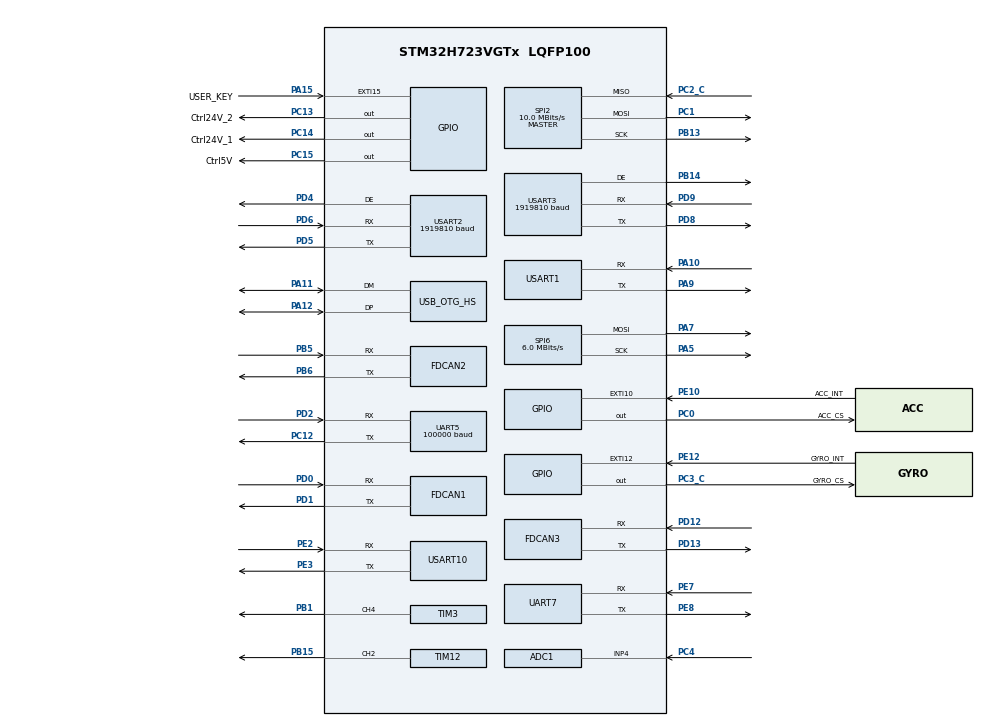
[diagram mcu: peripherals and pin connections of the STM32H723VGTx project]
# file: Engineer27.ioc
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ADC1.Channel-0\#ChannelRegularConversion=ADC_CHANNEL_4
ADC1.ContinuousConvMode=ENABLE
ADC1.ConversionDataManagement=ADC_CONVERSIONDATA_DMA_CIRCULAR
ADC1.NbrOfConversionFlag=1
ADC1.OffsetNumber-0\#ChannelRegularConversion=ADC_OFFSET_NONE
ADC1.OffsetSignedSaturation-0\#ChannelRegularConversion=DISABLE
ADC1.Overrun=ADC_OVR_DATA_OVERWRITTEN
ADC1.Rank-0\#ChannelRegularConversion=1
ADC1.SamplingTime-0\#ChannelRegularConversion=ADC_SAMPLETIME_64CYCLES_5
ADC1.master=1
ADC3.Channel-0\#ChannelRegularConversion=ADC_CHANNEL_TEMPSENSOR
ADC3.ContinuousConvMode=ENABLE
ADC3.ConversionDataManagement=ADC_CONVERSIONDATA_DMA_CIRCULAR
ADC3.DMAContinuousRequests=ENABLE
ADC3.NbrOfConversionFlag=1
ADC3.OffsetNumber-0\#ChannelRegularConversion=ADC_OFFSET_NONE
ADC3.OffsetSign-0\#ChannelRegularConversion=ADC3_OFFSET_SIGN_NEGATIVE
ADC3.Overrun=ADC_OVR_DATA_OVERWRITTEN
ADC3.Rank-0\#ChannelRegularConversion=1
ADC3.SamplingTime-0\#ChannelRegularConversion=ADC3_SAMPLETIME_92CYCLES_5
Bdma.ADC3.1.Direction=DMA_PERIPH_TO_MEMORY
Bdma.ADC3.1.EventEnable=DISABLE
Bdma.ADC3.1.Instance=BDMA_Channel1
Bdma.ADC3.1.MemDataAlignment=DMA_MDATAALIGN_HALFWORD
Bdma.ADC3.1.MemInc=DMA_MINC_ENABLE
Bdma.ADC3.1.Mode=DMA_CIRCULAR
Bdma.ADC3.1.PeriphDataAlignment=DMA_PDATAALIGN_HALFWORD
Bdma.ADC3.1.PeriphInc=DMA_PINC_DISABLE
Bdma.ADC3.1.Polarity=HAL_DMAMUX_REQ_GEN_RISING
Bdma.ADC3.1.Priority=DMA_PRIORITY_LOW
Bdma.ADC3.1.RequestNumber=1
Bdma.ADC3.1.SignalID=NONE
Bdma.ADC3.1.SyncEnable=DISABLE
Bdma.ADC3.1.SyncPolarity=HAL_DMAMUX_SYNC_NO_EVENT
Bdma.ADC3.1.SyncRequestNumber=1
Bdma.ADC3.1.SyncSignalID=NONE
Bdma.Request0=SPI6_TX
Bdma.Request1=ADC3
Bdma.RequestsNb=2
Bdma.SPI6_TX.0.Direction=DMA_MEMORY_TO_PERIPH
Bdma.SPI6_TX.0.EventEnable=DISABLE
Bdma.SPI6_TX.0.Instance=BDMA_Channel0
Bdma.SPI6_TX.0.MemDataAlignment=DMA_MDATAALIGN_BYTE
Bdma.SPI6_TX.0.MemInc=DMA_MINC_ENABLE
Bdma.SPI6_TX.0.Mode=DMA_NORMAL
Bdma.SPI6_TX.0.PeriphDataAlignment=DMA_PDATAALIGN_BYTE
Bdma.SPI6_TX.0.PeriphInc=DMA_PINC_DISABLE
Bdma.SPI6_TX.0.Polarity=HAL_DMAMUX_REQ_GEN_RISING
Bdma.SPI6_TX.0.Priority=DMA_PRIORITY_HIGH
Bdma.SPI6_TX.0.RequestNumber=1
Bdma.SPI6_TX.0.SignalID=NONE
Bdma.SPI6_TX.0.SyncEnable=DISABLE
Bdma.SPI6_TX.0.SyncPolarity=HAL_DMAMUX_SYNC_NO_EVENT
Bdma.SPI6_TX.0.SyncRequestNumber=1
Bdma.SPI6_TX.0.SyncSignalID=NONE
CORTEX_M7.AccessPermission_S-Cortex_Memory_Protection_Unit_Region1_Settings_S=MPU_REGION_FULL_ACCESS
CORTEX_M7.AccessPermission_S-Cortex_Memory_Protection_Unit_Region2_Settings_S=MPU_REGION_FULL_ACCESS
CORTEX_M7.AccessPermission_S-Cortex_Memory_Protection_Unit_Region3_Settings_S=MPU_REGION_FULL_ACCESS
CORTEX_M7.AccessPermission_S-Cortex_Memory_Protection_Unit_Region4_Settings_S=MPU_REGION_FULL_ACCESS
CORTEX_M7.AccessPermission_S-Cortex_Memory_Protection_Unit_Region5_Settings_S=MPU_REGION_FULL_ACCESS
CORTEX_M7.AccessPermission_S-Cortex_Memory_Protection_Unit_Region6_Settings_S=MPU_REGION_FULL_ACCESS
CORTEX_M7.AccessPermission_S-Cortex_Memory_Protection_Unit_Region7_Settings_S=MPU_REGION_FULL_ACCESS
CORTEX_M7.AccessPermission_Spec=MPU_REGION_NO_ACCESS
CORTEX_M7.BaseAddress_S-Cortex_Memory_Protection_Unit_Region1_Settings_S=0x00000000
CORTEX_M7.BaseAddress_S-Cortex_Memory_Protection_Unit_Region2_Settings_S=0x20000000
CORTEX_M7.BaseAddress_S-Cortex_Memory_Protection_Unit_Region3_Settings_S=0x24000000
CORTEX_M7.BaseAddress_S-Cortex_Memory_Protection_Unit_Region4_Settings_S=0x30000000
CORTEX_M7.BaseAddress_S-Cortex_Memory_Protection_Unit_Region5_Settings_S=0x38000000
CORTEX_M7.BaseAddress_S-Cortex_Memory_Protection_Unit_Region6_Settings_S=0x40000000
CORTEX_M7.BaseAddress_S-Cortex_Memory_Protection_Unit_Region7_Settings_S=0x8000000
CORTEX_M7.CPU_DCache=Enabled
CORTEX_M7.CPU_ICache=Enabled
CORTEX_M7.DisableExec_S-Cortex_Memory_Protection_Unit_Region2_Settings_S=MPU_INSTRUCTION_ACCESS_DISABLE
CORTEX_M7.DisableExec_S-Cortex_Memory_Protection_Unit_Region3_Settings_S=MPU_INSTRUCTION_ACCESS_DISABLE
CORTEX_M7.DisableExec_S-Cortex_Memory_Protection_Unit_Region4_Settings_S=MPU_INSTRUCTION_ACCESS_DISABLE
CORTEX_M7.DisableExec_S-Cortex_Memory_Protection_Unit_Region5_Settings_S=MPU_INSTRUCTION_ACCESS_DISABLE
CORTEX_M7.DisableExec_S-Cortex_Memory_Protection_Unit_Region6_Settings_S=MPU_INSTRUCTION_ACCESS_DISABLE
CORTEX_M7.DisableExec_Spec=MPU_INSTRUCTION_ACCESS_DISABLE
CORTEX_M7.Enable_S-Cortex_Memory_Protection_Unit_Region1_Settings_S=MPU_REGION_ENABLE
CORTEX_M7.Enable_S-Cortex_Memory_Protection_Unit_Region2_Settings_S=MPU_REGION_ENABLE
CORTEX_M7.Enable_S-Cortex_Memory_Protection_Unit_Region3_Settings_S=MPU_REGION_ENABLE
CORTEX_M7.Enable_S-Cortex_Memory_Protection_Unit_Region4_Settings_S=MPU_REGION_ENABLE
CORTEX_M7.Enable_S-Cortex_Memory_Protection_Unit_Region5_Settings_S=MPU_REGION_ENABLE
CORTEX_M7.Enable_S-Cortex_Memory_Protection_Unit_Region6_Settings_S=MPU_REGION_ENABLE
CORTEX_M7.Enable_S-Cortex_Memory_Protection_Unit_Region7_Settings_S=MPU_REGION_ENABLE
CORTEX_M7.IsBufferable_S-Cortex_Memory_Protection_Unit_Region3_Settings_S=MPU_ACCESS_BUFFERABLE
CORTEX_M7.IsBufferable_S-Cortex_Memory_Protection_Unit_Region6_Settings_S=MPU_ACCESS_BUFFERABLE
CORTEX_M7.IsBufferable_S-Cortex_Memory_Protection_Unit_Region7_Settings_S=MPU_ACCESS_BUFFERABLE
CORTEX_M7.IsCacheable_S-Cortex_Memory_Protection_Unit_Region3_Settings_S=MPU_ACCESS_CACHEABLE
CORTEX_M7.IsCacheable_S-Cortex_Memory_Protection_Unit_Region7_Settings_S=MPU_ACCESS_CACHEABLE
CORTEX_M7.IsShareable_S-Cortex_Memory_Protection_Unit_Region4_Settings_S=MPU_ACCESS_SHAREABLE
CORTEX_M7.IsShareable_S-Cortex_Memory_Protection_Unit_Region5_Settings_S=MPU_ACCESS_SHAREABLE
CORTEX_M7.IsShareable_S-Cortex_Memory_Protection_Unit_Region6_Settings_S=MPU_ACCESS_SHAREABLE
CORTEX_M7.IsShareable_Spec=MPU_ACCESS_NOT_SHAREABLE
CORTEX_M7.MPU_Control=MPU_PRIVILEGED_DEFAULT
CORTEX_M7.Size_S-Cortex_Memory_Protection_Unit_Region1_Settings_S=MPU_REGION_SIZE_64KB
CORTEX_M7.Size_S-Cortex_Memory_Protection_Unit_Region2_Settings_S=MPU_REGION_SIZE_128KB
CORTEX_M7.Size_S-Cortex_Memory_Protection_Unit_Region3_Settings_S=MPU_REGION_SIZE_512KB
CORTEX_M7.Size_S-Cortex_Memory_Protection_Unit_Region4_Settings_S=MPU_REGION_SIZE_32KB
CORTEX_M7.Size_S-Cortex_Memory_Protection_Unit_Region5_Settings_S=MPU_REGION_SIZE_16KB
CORTEX_M7.Size_S-Cortex_Memory_Protection_Unit_Region6_Settings_S=MPU_REGION_SIZE_512MB
CORTEX_M7.Size_S-Cortex_Memory_Protection_Unit_Region7_Settings_S=MPU_REGION_SIZE_1MB
CORTEX_M7.SubRegionDisable_S-Cortex_Memory_Protection_Unit_Region3_Settings_S=0xE0
CORTEX_M7.TypeExtField_S-Cortex_Memory_Protection_Unit_Region1_Settings_S=MPU_TEX_LEVEL1
CORTEX_M7.TypeExtField_S-Cortex_Memory_Protection_Unit_Region2_Settings_S=MPU_TEX_LEVEL1
CORTEX_M7.TypeExtField_S-Cortex_Memory_Protection_Unit_Region3_Settings_S=MPU_TEX_LEVEL1
CORTEX_M7.TypeExtField_S-Cortex_Memory_Protection_Unit_Region4_Settings_S=MPU_TEX_LEVEL1
CORTEX_M7.TypeExtField_S-Cortex_Memory_Protection_Unit_Region5_Settings_S=MPU_TEX_LEVEL1
CORTEX_M7.default_mode_Activation=1
CRC.CRCLength=CRC_POLYLENGTH_16B
CRC.DefaultInitValueUse=DEFAULT_INIT_VALUE_DISABLE
CRC.DefaultPolynomialUse=DEFAULT_POLYNOMIAL_DISABLE
CRC.GeneratingPolynomial=X12+X5+X0
CRC.InitValue=0xFFFF
CRC.InputDataInversionMode=CRC_INPUTDATA_INVERSION_BYTE
CRC.OutputDataInversionMode=CRC_OUTPUTDATA_INVERSION_ENABLE
Dma.ADC1.13.Direction=DMA_PERIPH_TO_MEMORY
Dma.ADC1.13.EventEnable=DISABLE
Dma.ADC1.13.FIFOMode=DMA_FIFOMODE_DISABLE
Dma.ADC1.13.Instance=DMA2_Stream5
Dma.ADC1.13.MemDataAlignment=DMA_MDATAALIGN_HALFWORD
Dma.ADC1.13.MemInc=DMA_MINC_ENABLE
Dma.ADC1.13.Mode=DMA_CIRCULAR
Dma.ADC1.13.PeriphDataAlignment=DMA_PDATAALIGN_HALFWORD
Dma.ADC1.13.PeriphInc=DMA_PINC_DISABLE
Dma.ADC1.13.Polarity=HAL_DMAMUX_REQ_GEN_RISING
Dma.ADC1.13.Priority=DMA_PRIORITY_LOW
Dma.ADC1.13.RequestNumber=1
Dma.ADC1.13.SignalID=NONE
Dma.ADC1.13.SyncEnable=DISABLE
Dma.ADC1.13.SyncPolarity=HAL_DMAMUX_SYNC_NO_EVENT
Dma.ADC1.13.SyncRequestNumber=1
Dma.ADC1.13.SyncSignalID=NONE
Dma.Request0=SPI2_RX
Dma.Request1=SPI2_TX
Dma.Request10=USART1_TX
Dma.Request11=USART10_RX
Dma.Request12=USART10_TX
Dma.Request13=ADC1
Dma.Request2=UART7_RX
Dma.Request3=UART7_TX
Dma.Request4=UART5_RX
Dma.Request5=USART2_TX
Dma.Request6=USART2_RX
Dma.Request7=USART3_TX
Dma.Request8=USART3_RX
Dma.Request9=USART1_RX
Dma.SPI2_RX.0.Direction=DMA_PERIPH_TO_MEMORY
Dma.SPI2_RX.0.EventEnable=DISABLE
Dma.SPI2_RX.0.FIFOMode=DMA_FIFOMODE_DISABLE
Dma.SPI2_RX.0.Instance=DMA1_Stream0
Dma.SPI2_RX.0.MemDataAlignment=DMA_MDATAALIGN_BYTE
Dma.SPI2_RX.0.MemInc=DMA_MINC_ENABLE
Dma.SPI2_RX.0.Mode=DMA_NORMAL
Dma.SPI2_RX.0.PeriphDataAlignment=DMA_PDATAALIGN_BYTE
Dma.SPI2_RX.0.PeriphInc=DMA_PINC_DISABLE
Dma.SPI2_RX.0.Polarity=HAL_DMAMUX_REQ_GEN_RISING
Dma.SPI2_RX.0.Priority=DMA_PRIORITY_VERY_HIGH
Dma.SPI2_RX.0.RequestNumber=1
Dma.SPI2_RX.0.SignalID=NONE
Dma.SPI2_RX.0.SyncEnable=DISABLE
Dma.SPI2_RX.0.SyncPolarity=HAL_DMAMUX_SYNC_NO_EVENT
Dma.SPI2_RX.0.SyncRequestNumber=1
Dma.SPI2_RX.0.SyncSignalID=NONE
Dma.SPI2_TX.1.Direction=DMA_MEMORY_TO_PERIPH
Dma.SPI2_TX.1.EventEnable=DISABLE
Dma.SPI2_TX.1.FIFOMode=DMA_FIFOMODE_DISABLE
Dma.SPI2_TX.1.Instance=DMA1_Stream1
Dma.SPI2_TX.1.MemDataAlignment=DMA_MDATAALIGN_BYTE
Dma.SPI2_TX.1.MemInc=DMA_MINC_ENABLE
Dma.SPI2_TX.1.Mode=DMA_NORMAL
Dma.SPI2_TX.1.PeriphDataAlignment=DMA_PDATAALIGN_BYTE
Dma.SPI2_TX.1.PeriphInc=DMA_PINC_DISABLE
Dma.SPI2_TX.1.Polarity=HAL_DMAMUX_REQ_GEN_RISING
Dma.SPI2_TX.1.Priority=DMA_PRIORITY_HIGH
Dma.SPI2_TX.1.RequestNumber=1
Dma.SPI2_TX.1.SignalID=NONE
Dma.SPI2_TX.1.SyncEnable=DISABLE
Dma.SPI2_TX.1.SyncPolarity=HAL_DMAMUX_SYNC_NO_EVENT
Dma.SPI2_TX.1.SyncRequestNumber=1
Dma.SPI2_TX.1.SyncSignalID=NONE
Dma.UART5_RX.4.Direction=DMA_PERIPH_TO_MEMORY
Dma.UART5_RX.4.EventEnable=DISABLE
Dma.UART5_RX.4.FIFOMode=DMA_FIFOMODE_DISABLE
Dma.UART5_RX.4.Instance=DMA2_Stream2
Dma.UART5_RX.4.MemDataAlignment=DMA_MDATAALIGN_BYTE
Dma.UART5_RX.4.MemInc=DMA_MINC_ENABLE
Dma.UART5_RX.4.Mode=DMA_NORMAL
Dma.UART5_RX.4.PeriphDataAlignment=DMA_PDATAALIGN_BYTE
Dma.UART5_RX.4.PeriphInc=DMA_PINC_DISABLE
Dma.UART5_RX.4.Polarity=HAL_DMAMUX_REQ_GEN_RISING
Dma.UART5_RX.4.Priority=DMA_PRIORITY_VERY_HIGH
Dma.UART5_RX.4.RequestNumber=1
Dma.UART5_RX.4.SignalID=NONE
Dma.UART5_RX.4.SyncEnable=DISABLE
Dma.UART5_RX.4.SyncPolarity=HAL_DMAMUX_SYNC_NO_EVENT
Dma.UART5_RX.4.SyncRequestNumber=1
Dma.UART5_RX.4.SyncSignalID=NONE
Dma.UART7_RX.2.Direction=DMA_PERIPH_TO_MEMORY
Dma.UART7_RX.2.EventEnable=DISABLE
Dma.UART7_RX.2.FIFOMode=DMA_FIFOMODE_DISABLE
Dma.UART7_RX.2.Instance=DMA2_Stream0
Dma.UART7_RX.2.MemDataAlignment=DMA_MDATAALIGN_BYTE
Dma.UART7_RX.2.MemInc=DMA_MINC_ENABLE
Dma.UART7_RX.2.Mode=DMA_NORMAL
Dma.UART7_RX.2.PeriphDataAlignment=DMA_PDATAALIGN_BYTE
Dma.UART7_RX.2.PeriphInc=DMA_PINC_DISABLE
Dma.UART7_RX.2.Polarity=HAL_DMAMUX_REQ_GEN_RISING
Dma.UART7_RX.2.Priority=DMA_PRIORITY_MEDIUM
Dma.UART7_RX.2.RequestNumber=1
Dma.UART7_RX.2.SignalID=NONE
Dma.UART7_RX.2.SyncEnable=DISABLE
Dma.UART7_RX.2.SyncPolarity=HAL_DMAMUX_SYNC_NO_EVENT
Dma.UART7_RX.2.SyncRequestNumber=1
Dma.UART7_RX.2.SyncSignalID=NONE
Dma.UART7_TX.3.Direction=DMA_MEMORY_TO_PERIPH
Dma.UART7_TX.3.EventEnable=DISABLE
Dma.UART7_TX.3.FIFOMode=DMA_FIFOMODE_DISABLE
Dma.UART7_TX.3.Instance=DMA2_Stream1
Dma.UART7_TX.3.MemDataAlignment=DMA_MDATAALIGN_BYTE
Dma.UART7_TX.3.MemInc=DMA_MINC_ENABLE
Dma.UART7_TX.3.Mode=DMA_NORMAL
Dma.UART7_TX.3.PeriphDataAlignment=DMA_PDATAALIGN_BYTE
Dma.UART7_TX.3.PeriphInc=DMA_PINC_DISABLE
Dma.UART7_TX.3.Polarity=HAL_DMAMUX_REQ_GEN_RISING
Dma.UART7_TX.3.Priority=DMA_PRIORITY_MEDIUM
Dma.UART7_TX.3.RequestNumber=1
Dma.UART7_TX.3.SignalID=NONE
Dma.UART7_TX.3.SyncEnable=DISABLE
Dma.UART7_TX.3.SyncPolarity=HAL_DMAMUX_SYNC_NO_EVENT
Dma.UART7_TX.3.SyncRequestNumber=1
Dma.UART7_TX.3.SyncSignalID=NONE
Dma.USART10_RX.11.Direction=DMA_PERIPH_TO_MEMORY
Dma.USART10_RX.11.EventEnable=DISABLE
Dma.USART10_RX.11.FIFOMode=DMA_FIFOMODE_DISABLE
Dma.USART10_RX.11.Instance=DMA2_Stream3
Dma.USART10_RX.11.MemDataAlignment=DMA_MDATAALIGN_BYTE
Dma.USART10_RX.11.MemInc=DMA_MINC_ENABLE
Dma.USART10_RX.11.Mode=DMA_NORMAL
Dma.USART10_RX.11.PeriphDataAlignment=DMA_PDATAALIGN_BYTE
Dma.USART10_RX.11.PeriphInc=DMA_PINC_DISABLE
Dma.USART10_RX.11.Polarity=HAL_DMAMUX_REQ_GEN_RISING
Dma.USART10_RX.11.Priority=DMA_PRIORITY_LOW
Dma.USART10_RX.11.RequestNumber=1
Dma.USART10_RX.11.SignalID=NONE
Dma.USART10_RX.11.SyncEnable=DISABLE
Dma.USART10_RX.11.SyncPolarity=HAL_DMAMUX_SYNC_NO_EVENT
Dma.USART10_RX.11.SyncRequestNumber=1
Dma.USART10_RX.11.SyncSignalID=NONE
Dma.USART10_TX.12.Direction=DMA_MEMORY_TO_PERIPH
Dma.USART10_TX.12.EventEnable=DISABLE
Dma.USART10_TX.12.FIFOMode=DMA_FIFOMODE_DISABLE
Dma.USART10_TX.12.Instance=DMA2_Stream4
Dma.USART10_TX.12.MemDataAlignment=DMA_MDATAALIGN_BYTE
Dma.USART10_TX.12.MemInc=DMA_MINC_ENABLE
Dma.USART10_TX.12.Mode=DMA_NORMAL
Dma.USART10_TX.12.PeriphDataAlignment=DMA_PDATAALIGN_BYTE
Dma.USART10_TX.12.PeriphInc=DMA_PINC_DISABLE
Dma.USART10_TX.12.Polarity=HAL_DMAMUX_REQ_GEN_RISING
Dma.USART10_TX.12.Priority=DMA_PRIORITY_LOW
Dma.USART10_TX.12.RequestNumber=1
Dma.USART10_TX.12.SignalID=NONE
Dma.USART10_TX.12.SyncEnable=DISABLE
Dma.USART10_TX.12.SyncPolarity=HAL_DMAMUX_SYNC_NO_EVENT
Dma.USART10_TX.12.SyncRequestNumber=1
Dma.USART10_TX.12.SyncSignalID=NONE
Dma.USART1_RX.9.Direction=DMA_PERIPH_TO_MEMORY
Dma.USART1_RX.9.EventEnable=DISABLE
Dma.USART1_RX.9.FIFOMode=DMA_FIFOMODE_DISABLE
Dma.USART1_RX.9.Instance=DMA1_Stream6
Dma.USART1_RX.9.MemDataAlignment=DMA_MDATAALIGN_BYTE
Dma.USART1_RX.9.MemInc=DMA_MINC_ENABLE
Dma.USART1_RX.9.Mode=DMA_NORMAL
Dma.USART1_RX.9.PeriphDataAlignment=DMA_PDATAALIGN_BYTE
Dma.USART1_RX.9.PeriphInc=DMA_PINC_DISABLE
Dma.USART1_RX.9.Polarity=HAL_DMAMUX_REQ_GEN_RISING
Dma.USART1_RX.9.Priority=DMA_PRIORITY_LOW
Dma.USART1_RX.9.RequestNumber=1
Dma.USART1_RX.9.SignalID=NONE
Dma.USART1_RX.9.SyncEnable=DISABLE
Dma.USART1_RX.9.SyncPolarity=HAL_DMAMUX_SYNC_NO_EVENT
Dma.USART1_RX.9.SyncRequestNumber=1
Dma.USART1_RX.9.SyncSignalID=NONE
Dma.USART1_TX.10.Direction=DMA_MEMORY_TO_PERIPH
Dma.USART1_TX.10.EventEnable=DISABLE
Dma.USART1_TX.10.FIFOMode=DMA_FIFOMODE_DISABLE
Dma.USART1_TX.10.Instance=DMA1_Stream7
Dma.USART1_TX.10.MemDataAlignment=DMA_MDATAALIGN_BYTE
Dma.USART1_TX.10.MemInc=DMA_MINC_ENABLE
Dma.USART1_TX.10.Mode=DMA_NORMAL
Dma.USART1_TX.10.PeriphDataAlignment=DMA_PDATAALIGN_BYTE
Dma.USART1_TX.10.PeriphInc=DMA_PINC_DISABLE
Dma.USART1_TX.10.Polarity=HAL_DMAMUX_REQ_GEN_RISING
Dma.USART1_TX.10.Priority=DMA_PRIORITY_LOW
Dma.USART1_TX.10.RequestNumber=1
Dma.USART1_TX.10.SignalID=NONE
Dma.USART1_TX.10.SyncEnable=DISABLE
Dma.USART1_TX.10.SyncPolarity=HAL_DMAMUX_SYNC_NO_EVENT
Dma.USART1_TX.10.SyncRequestNumber=1
Dma.USART1_TX.10.SyncSignalID=NONE
Dma.USART2_RX.6.Direction=DMA_PERIPH_TO_MEMORY
Dma.USART2_RX.6.EventEnable=DISABLE
Dma.USART2_RX.6.FIFOMode=DMA_FIFOMODE_DISABLE
Dma.USART2_RX.6.Instance=DMA1_Stream3
Dma.USART2_RX.6.MemDataAlignment=DMA_MDATAALIGN_BYTE
Dma.USART2_RX.6.MemInc=DMA_MINC_ENABLE
Dma.USART2_RX.6.Mode=DMA_NORMAL
Dma.USART2_RX.6.PeriphDataAlignment=DMA_PDATAALIGN_BYTE
Dma.USART2_RX.6.PeriphInc=DMA_PINC_DISABLE
Dma.USART2_RX.6.Polarity=HAL_DMAMUX_REQ_GEN_RISING
Dma.USART2_RX.6.Priority=DMA_PRIORITY_HIGH
Dma.USART2_RX.6.RequestNumber=1
Dma.USART2_RX.6.SignalID=NONE
Dma.USART2_RX.6.SyncEnable=DISABLE
Dma.USART2_RX.6.SyncPolarity=HAL_DMAMUX_SYNC_NO_EVENT
Dma.USART2_RX.6.SyncRequestNumber=1
Dma.USART2_RX.6.SyncSignalID=NONE
Dma.USART2_TX.5.Direction=DMA_MEMORY_TO_PERIPH
Dma.USART2_TX.5.EventEnable=DISABLE
Dma.USART2_TX.5.FIFOMode=DMA_FIFOMODE_DISABLE
Dma.USART2_TX.5.Instance=DMA1_Stream2
Dma.USART2_TX.5.MemDataAlignment=DMA_MDATAALIGN_BYTE
Dma.USART2_TX.5.MemInc=DMA_MINC_ENABLE
Dma.USART2_TX.5.Mode=DMA_NORMAL
Dma.USART2_TX.5.PeriphDataAlignment=DMA_PDATAALIGN_BYTE
Dma.USART2_TX.5.PeriphInc=DMA_PINC_DISABLE
Dma.USART2_TX.5.Polarity=HAL_DMAMUX_REQ_GEN_RISING
Dma.USART2_TX.5.Priority=DMA_PRIORITY_HIGH
Dma.USART2_TX.5.RequestNumber=1
Dma.USART2_TX.5.SignalID=NONE
Dma.USART2_TX.5.SyncEnable=DISABLE
Dma.USART2_TX.5.SyncPolarity=HAL_DMAMUX_SYNC_NO_EVENT
Dma.USART2_TX.5.SyncRequestNumber=1
Dma.USART2_TX.5.SyncSignalID=NONE
Dma.USART3_RX.8.Direction=DMA_PERIPH_TO_MEMORY
Dma.USART3_RX.8.EventEnable=DISABLE
Dma.USART3_RX.8.FIFOMode=DMA_FIFOMODE_DISABLE
Dma.USART3_RX.8.Instance=DMA1_Stream5
Dma.USART3_RX.8.MemDataAlignment=DMA_MDATAALIGN_BYTE
Dma.USART3_RX.8.MemInc=DMA_MINC_ENABLE
Dma.USART3_RX.8.Mode=DMA_NORMAL
Dma.USART3_RX.8.PeriphDataAlignment=DMA_PDATAALIGN_BYTE
Dma.USART3_RX.8.PeriphInc=DMA_PINC_DISABLE
Dma.USART3_RX.8.Polarity=HAL_DMAMUX_REQ_GEN_RISING
Dma.USART3_RX.8.Priority=DMA_PRIORITY_HIGH
Dma.USART3_RX.8.RequestNumber=1
Dma.USART3_RX.8.SignalID=NONE
Dma.USART3_RX.8.SyncEnable=DISABLE
Dma.USART3_RX.8.SyncPolarity=HAL_DMAMUX_SYNC_NO_EVENT
Dma.USART3_RX.8.SyncRequestNumber=1
Dma.USART3_RX.8.SyncSignalID=NONE
Dma.USART3_TX.7.Direction=DMA_MEMORY_TO_PERIPH
Dma.USART3_TX.7.EventEnable=DISABLE
Dma.USART3_TX.7.FIFOMode=DMA_FIFOMODE_DISABLE
Dma.USART3_TX.7.Instance=DMA1_Stream4
Dma.USART3_TX.7.MemDataAlignment=DMA_MDATAALIGN_BYTE
Dma.USART3_TX.7.MemInc=DMA_MINC_ENABLE
Dma.USART3_TX.7.Mode=DMA_NORMAL
Dma.USART3_TX.7.PeriphDataAlignment=DMA_PDATAALIGN_BYTE
Dma.USART3_TX.7.PeriphInc=DMA_PINC_DISABLE
Dma.USART3_TX.7.Polarity=HAL_DMAMUX_REQ_GEN_RISING
Dma.USART3_TX.7.Priority=DMA_PRIORITY_HIGH
Dma.USART3_TX.7.RequestNumber=1
Dma.USART3_TX.7.SignalID=NONE
Dma.USART3_TX.7.SyncEnable=DISABLE
Dma.USART3_TX.7.SyncPolarity=HAL_DMAMUX_SYNC_NO_EVENT
Dma.USART3_TX.7.SyncRequestNumber=1
Dma.USART3_TX.7.SyncSignalID=NONE
FDCAN1.AutoRetransmission=ENABLE
FDCAN1.CalculateBaudRateNominal=1000000
FDCAN1.CalculateTimeBitNominal=1000
FDCAN1.CalculateTimeQuantumNominal=12.5
FDCAN1.ClockCalibrationCCU=DISABLE
FDCAN1.DataPrescaler=2
FDCAN1.DataSyncJumpWidth=8
FDCAN1.DataTimeSeg1=31
FDCAN1.DataTimeSeg2=8
FDCAN1.ExtFiltersNbr=1
FDCAN1.FrameFormat=FDCAN_FRAME_FD_BRS
FDCAN1.NominalPrescaler=1
FDCAN1.NominalSyncJumpWidth=20
FDCAN1.NominalTimeSeg1=59
FDCAN1.NominalTimeSeg2=20
FDCAN1.ProtocolException=ENABLE
FDCAN1.RxFifo0ElmtsNbr=16
FDCAN1.StdFiltersNbr=1
FDCAN1.TransmitPause=ENABLE
FDCAN1.TxEventsNbr=8
FDCAN1.TxFifoQueueElmtsNbr=32
FDCAN2.AutoRetransmission=ENABLE
FDCAN2.CalculateBaudRateNominal=1000000
FDCAN2.CalculateTimeBitNominal=1000
FDCAN2.CalculateTimeQuantumNominal=12.5
FDCAN2.DataPrescaler=1
FDCAN2.DataSyncJumpWidth=8
FDCAN2.DataTimeSeg1=31
FDCAN2.DataTimeSeg2=8
FDCAN2.ExtFiltersNbr=1
FDCAN2.FrameFormat=FDCAN_FRAME_FD_BRS
FDCAN2.MessageRAMOffset=0x406
FDCAN2.NominalPrescaler=1
FDCAN2.NominalSyncJumpWidth=20
FDCAN2.NominalTimeSeg1=59
FDCAN2.NominalTimeSeg2=20
FDCAN2.ProtocolException=ENABLE
FDCAN2.RxFifo0ElmtsNbr=0
FDCAN2.RxFifo1ElmtsNbr=16
FDCAN2.StdFiltersNbr=1
FDCAN2.TransmitPause=ENABLE
FDCAN2.TxEventsNbr=8
FDCAN2.TxFifoQueueElmtsNbr=32
FDCAN3.AutoRetransmission=DISABLE
FDCAN3.CalculateBaudRateNominal=1000000
FDCAN3.CalculateTimeBitNominal=1000
FDCAN3.CalculateTimeQuantumNominal=12.5
FDCAN3.DataSyncJumpWidth=8
FDCAN3.DataTimeSeg1=31
FDCAN3.DataTimeSeg2=8
FDCAN3.ExtFiltersNbr=1
FDCAN3.FrameFormat=FDCAN_FRAME_FD_BRS
FDCAN3.MessageRAMOffset=0x812
FDCAN3.NominalPrescaler=1
FDCAN3.NominalSyncJumpWidth=20
FDCAN3.NominalTimeSeg1=59
FDCAN3.NominalTimeSeg2=20
FDCAN3.ProtocolException=ENABLE
FDCAN3.RxFifo0ElmtsNbr=0
FDCAN3.RxFifo1ElmtsNbr=16
FDCAN3.StdFiltersNbr=1
FDCAN3.TransmitPause=ENABLE
FDCAN3.TxEventsNbr=8
FDCAN3.TxFifoQueueElmtsNbr=32
FREERTOS.INCLUDE_eTaskGetState=1
FREERTOS.INCLUDE_uxTaskGetStackHighWaterMark=1
FREERTOS.INCLUDE_uxTaskGetStackHighWaterMark2=0
FREERTOS.INCLUDE_uxTaskPriorityGet=1
FREERTOS.INCLUDE_vTaskDelayUntil=1
FREERTOS.INCLUDE_vTaskPrioritySet=1
FREERTOS.INCLUDE_xQueueGetMutexHolder=0
FREERTOS.INCLUDE_xSemaphoreGetMutexHolder=1
FREERTOS.INCLUDE_xTaskGetSchedulerState=1
FREERTOS.INCLUDE_xTaskResumeFromISR=0
FREERTOS.INCLUDE_xTimerPendFunctionCall=0
FREERTOS.Tasks01=defaultTask,48,256,TaskStart,As weak,NULL,Dynamic,NULL,NULL;errorTask,40,256,TaskError,As external,NULL,Dynamic,NULL,NULL;remoteCtrlTask,40,256,TaskRemoteCtrl,As external,NULL,Dynamic,NULL,NULL;daemonTask,24,256,TaskDaemon,As external,NULL,Dynamic,NULL,NULL;hostTask,40,256,TaskHost,As external,NULL,Dynamic,NULL,NULL;wdgTask,16,128,Taskwdg,As external,NULL,Dynamic,NULL,NULL;chassisTask,24,256,TaskChassis,As external,NULL,Dynamic,NULL,NULL;roboarmTask,24,512,TaskRoboarm,As external,NULL,Dynamic,NULL,NULL;imuTask,40,256,TaskImu,As external,NULL,Dynamic,NULL,NULL;refereeTask,40,256,TaskReferee,As external,NULL,Dynamic,NULL,NULL
FREERTOS.configCHECK_FOR_STACK_OVERFLOW=0
FREERTOS.configENABLE_FPU=1
FREERTOS.configGENERATE_RUN_TIME_STATS=0
FREERTOS.configRECORD_STACK_HIGH_ADDRESS=1
FREERTOS.configTOTAL_HEAP_SIZE=20480
FREERTOS.configUSE_NEWLIB_REENTRANT=0
FREERTOS.configUSE_OS2_EVENTFLAGS_FROM_ISR=0
FREERTOS.configUSE_OS2_MUTEX=0
FREERTOS.configUSE_OS2_THREAD_ENUMERATE=0
FREERTOS.configUSE_OS2_THREAD_FLAGS=1
FREERTOS.configUSE_OS2_TIMER=0
FREERTOS.configUSE_TRACE_FACILITY=0
IWDG1.Prescaler=IWDG_PRESCALER_8
Mcu.Family=STM32H7
Mcu.Name=STM32H723VGTx
Mcu.Package=LQFP100
NVIC.BDMA_Channel0_IRQn=true\:5\:0\:false\:false\:true\:true\:false\:true\:true
NVIC.BDMA_Channel1_IRQn=true\:5\:0\:false\:false\:true\:true\:false\:true\:true
NVIC.DMA1_Stream0_IRQn=true\:5\:0\:false\:false\:true\:true\:false\:true\:true
NVIC.DMA1_Stream1_IRQn=true\:5\:0\:false\:false\:true\:true\:false\:true\:true
NVIC.DMA1_Stream2_IRQn=true\:5\:0\:false\:false\:true\:true\:false\:true\:true
NVIC.DMA1_Stream3_IRQn=true\:5\:0\:false\:false\:true\:true\:false\:true\:true
NVIC.DMA1_Stream4_IRQn=true\:5\:0\:false\:false\:true\:true\:false\:true\:true
NVIC.DMA1_Stream5_IRQn=true\:5\:0\:false\:false\:true\:true\:false\:true\:true
NVIC.DMA1_Stream6_IRQn=true\:5\:0\:false\:false\:true\:true\:false\:true\:true
NVIC.DMA1_Stream7_IRQn=true\:5\:0\:false\:false\:true\:true\:false\:true\:true
NVIC.DMA2_Stream0_IRQn=true\:5\:0\:false\:false\:true\:true\:false\:true\:true
NVIC.DMA2_Stream1_IRQn=true\:5\:0\:false\:false\:true\:false\:false\:true\:true
NVIC.DMA2_Stream2_IRQn=true\:5\:0\:false\:false\:true\:false\:false\:true\:true
NVIC.DMA2_Stream3_IRQn=true\:5\:0\:false\:false\:true\:true\:false\:true\:true
NVIC.DMA2_Stream4_IRQn=true\:5\:0\:false\:false\:true\:true\:false\:true\:true
NVIC.DMA2_Stream5_IRQn=true\:5\:0\:false\:false\:true\:true\:false\:true\:true
NVIC.EXTI15_10_IRQn=true\:5\:0\:false\:false\:true\:true\:true\:true\:true
NVIC.FDCAN1_IT0_IRQn=true\:5\:0\:false\:false\:true\:true\:true\:true\:true
NVIC.FDCAN2_IT0_IRQn=true\:5\:0\:false\:false\:true\:true\:true\:true\:true
NVIC.FDCAN3_IT0_IRQn=true\:5\:0\:false\:false\:true\:true\:true\:true\:true
NVIC.OTG_HS_IRQn=true\:5\:0\:false\:false\:true\:true\:true\:true\:true
NVIC.PriorityGroup=NVIC_PRIORITYGROUP_4
NVIC.SPI2_IRQn=true\:5\:0\:false\:false\:true\:true\:false\:true\:true
NVIC.SPI6_IRQn=true\:5\:0\:false\:false\:true\:true\:false\:true\:true
NVIC.TIM6_DAC_IRQn=true\:15\:0\:false\:false\:true\:false\:false\:true\:true
NVIC.TimeBase=TIM6_DAC_IRQn
NVIC.TimeBaseIP=TIM6
NVIC.UART5_IRQn=true\:5\:0\:false\:false\:true\:true\:true\:true\:true
NVIC.UART7_IRQn=true\:5\:0\:false\:false\:true\:true\:true\:true\:true
NVIC.USART10_IRQn=true\:5\:0\:false\:false\:true\:true\:true\:true\:true
NVIC.USART1_IRQn=true\:5\:0\:false\:false\:true\:true\:true\:true\:true
NVIC.USART2_IRQn=true\:5\:0\:false\:false\:true\:true\:true\:true\:true
NVIC.USART3_IRQn=true\:5\:0\:false\:false\:true\:true\:true\:true\:true
PA10.Mode=Asynchronous
PA10.Signal=USART1_RX
PA11.Mode=Device_Only_FS
PA11.Signal=USB_OTG_HS_DM
PA12.Mode=Device_Only_FS
PA12.Signal=USB_OTG_HS_DP
PA13(JTMS/SWDIO).Mode=Serial_Wire
PA13(JTMS/SWDIO).Signal=DEBUG_JTMS-SWDIO
PA14(JTCK/SWCLK).Mode=Serial_Wire
PA14(JTCK/SWCLK).Signal=DEBUG_JTCK-SWCLK
PA15(JTDI).GPIO_Label=USER_KEY
PA15(JTDI).GPIO_ModeDefaultEXTI=GPIO_MODE_IT_FALLING
PA15(JTDI).GPIO_PuPd=GPIO_PULLUP
PA15(JTDI).Signal=GPXTI15
PA5.GPIO_Speed=GPIO_SPEED_FREQ_VERY_HIGH
PA5.Mode=TX_Only_Simplex_Unidirect_Master
PA5.Signal=SPI6_SCK
PA7.GPIO_Speed=GPIO_SPEED_FREQ_VERY_HIGH
PA7.Mode=TX_Only_Simplex_Unidirect_Master
PA7.Signal=SPI6_MOSI
PA9.Mode=Asynchronous
PA9.Signal=USART1_TX
PB1.Signal=S_TIM3_CH4
PB13.GPIO_Speed=GPIO_SPEED_FREQ_VERY_HIGH
PB13.Mode=Full_Duplex_Master
PB13.Signal=SPI2_SCK
PB14.Mode=Hardware Flow Control (RS485)
PB14.Signal=USART3_DE
PB15.Signal=S_TIM12_CH2
PB5.Mode=FDCAN_Activate
PB5.Signal=FDCAN2_RX
PB6.Mode=FDCAN_Activate
PB6.Signal=FDCAN2_TX
PC0.GPIO_Label=ACC_CS
PC0.GPIO_Speed=GPIO_SPEED_FREQ_VERY_HIGH
PC0.PinState=GPIO_PIN_SET
PC0.Signal=GPIO_Output
PC1.GPIO_Speed=GPIO_SPEED_FREQ_VERY_HIGH
PC1.Mode=Full_Duplex_Master
PC1.Signal=SPI2_MOSI
PC12.Mode=Asynchronous
PC12.Signal=UART5_TX
PC13.GPIO_Label=Ctrl24V_2
PC13.Signal=GPIO_Output
PC14-OSC32_IN.GPIO_Label=Ctrl24V_1
PC14-OSC32_IN.Signal=GPIO_Output
PC15-OSC32_OUT.GPIO_Label=Ctrl5V
PC15-OSC32_OUT.Signal=GPIO_Output
PC2_C.GPIO_Speed=GPIO_SPEED_FREQ_VERY_HIGH
PC2_C.Mode=Full_Duplex_Master
PC2_C.Signal=SPI2_MISO
PC3_C.GPIO_Label=GYRO_CS
PC3_C.GPIO_Speed=GPIO_SPEED_FREQ_VERY_HIGH
PC3_C.PinState=GPIO_PIN_SET
PC3_C.Signal=GPIO_Output
PC4.Signal=ADCx_INP4
PD0.Mode=FDCAN_Activate
PD0.Signal=FDCAN1_RX
PD1.Mode=FDCAN_Activate
PD1.Signal=FDCAN1_TX
PD12.Mode=FDCAN_Activate
PD12.Signal=FDCAN3_RX
PD13.Mode=FDCAN_Activate
PD13.Signal=FDCAN3_TX
PD2.GPIO_PuPd=GPIO_NOPULL
PD2.Mode=Asynchronous
PD2.Signal=UART5_RX
PD4.Mode=Hardware Flow Control (RS485)
PD4.Signal=USART2_DE
PD5.Mode=Asynchronous
PD5.Signal=USART2_TX
PD6.Mode=Asynchronous
PD6.Signal=USART2_RX
PD8.Mode=Asynchronous
PD8.Signal=USART3_TX
PD9.Mode=Asynchronous
PD9.Signal=USART3_RX
PE10.GPIO_Label=ACC_INT
PE10.Signal=GPXTI10
PE12.GPIO_Label=GYRO_INT
PE12.Signal=GPXTI12
PE2.Mode=Asynchronous
PE2.Signal=USART10_RX
PE3.Mode=Asynchronous
PE3.Signal=USART10_TX
PE7.Mode=Asynchronous
PE7.Signal=UART7_RX
PE8.Mode=Asynchronous
PE8.Signal=UART7_TX
PH0-OSC_IN.Mode=HSE-External-Oscillator
PH0-OSC_IN.Signal=RCC_OSC_IN
PH1-OSC_OUT.Mode=HSE-External-Oscillator
PH1-OSC_OUT.Signal=RCC_OSC_OUT
ProjectManager.HeapSize=0x200
ProjectManager.StackSize=0x400
ProjectManager.TargetToolchain=CMake
RCC.ADCFreq_Value=80000000
RCC.APB1Freq_Value=137500000
RCC.APB2Freq_Value=137500000
RCC.APB3Freq_Value=137500000
RCC.APB4Freq_Value=137500000
RCC.CortexFreq_Value=550000000
RCC.D1PPRE=RCC_APB3_DIV2
RCC.D2PPRE1=RCC_APB1_DIV2
RCC.D2PPRE2=RCC_APB2_DIV2
RCC.D3PPRE=RCC_APB4_DIV2
RCC.DIVM1=3
RCC.DIVM2=8
RCC.DIVM3=16
RCC.DIVN1=68
RCC.DIVN2=80
RCC.DIVN3=160
RCC.DIVP1=1
RCC.DIVP2=3
RCC.DIVP3=1
RCC.DIVQ1=5
RCC.DIVQ2=3
RCC.DIVQ3=5
RCC.EnbaleCSS=false
RCC.FDCANCLockSelection=RCC_FDCANCLKSOURCE_PLL2
RCC.FLatency-AdvancedSettings=FLASH_LATENCY_3
RCC.HCLKFreq_Value=275000000
RCC.HPRE=RCC_HCLK_DIV2
RCC.HSE_VALUE=24000000
RCC.PLL1_VCI_Range-AdvancedSettings=RCC_PLL1VCIRANGE_0
RCC.PLL1_VCO_SEL-AdvancedSettings=RCC_PLL1VCOMEDIUM
RCC.PLL2FRACN=0
RCC.PLL2_VCI_Range-AdvancedSettings=RCC_PLL2VCIRANGE_0
RCC.PLL2_VCO_SEL-AdvancedSettings=RCC_PLL2VCOMEDIUM
RCC.PLL3_VCI_Range-AdvancedSettings=RCC_PLL3VCIRANGE_0
RCC.PLL3_VCO_SEL-AdvancedSettings=RCC_PLL3VCOWIDE
RCC.PLLFRACN=6144
RCC.PLLSourceVirtual=RCC_PLLSOURCE_HSE
RCC.SPI123CLockSelection=RCC_SPI123CLKSOURCE_PLL2
RCC.SPI6CLockSelection=RCC_SPI6CLKSOURCE_PLL3
RCC.SYSCLKFreq_VALUE=550000000
RCC.SYSCLKSource=RCC_SYSCLKSOURCE_PLLCLK
RCC.Tim1Mul=1
RCC.Tim2Mul=1
RCC.USBCLockSelection=RCC_USBCLKSOURCE_PLL3
RCC.USBFreq_Value=48000000
SH.ADCx_INP4.0=ADC1_INP4,IN4-Single-Ended
SH.S_TIM12_CH2.0=TIM12_CH2,PWM Generation2 CH2
SH.S_TIM3_CH4.0=TIM3_CH4,PWM Generation4 CH4
SPI2.BaudRatePrescaler=SPI_BAUDRATEPRESCALER_8
SPI2.CLKPhase=SPI_PHASE_2EDGE
SPI2.CLKPolarity=SPI_POLARITY_HIGH
SPI2.CalculateBaudRate=10.0 MBits/s
SPI2.DataSize=SPI_DATASIZE_8BIT
SPI2.Direction=SPI_DIRECTION_2LINES
SPI2.Mode=SPI_MODE_MASTER
SPI2.NSSPMode=SPI_NSS_PULSE_DISABLE
SPI2.VirtualType=VM_MASTER
SPI6.BaudRatePrescaler=SPI_BAUDRATEPRESCALER_8
SPI6.CLKPhase=SPI_PHASE_2EDGE
SPI6.CalculateBaudRate=6.0 MBits/s
SPI6.DataSize=SPI_DATASIZE_8BIT
SPI6.Direction=SPI_DIRECTION_2LINES_TXONLY
SPI6.Mode=SPI_MODE_MASTER
SPI6.VirtualType=VM_MASTER
TIM12.Channel-PWM\ Generation2\ CH2=TIM_CHANNEL_2
TIM23.Period=999
TIM23.Prescaler=274
TIM23.TIM_MasterOutputTrigger=TIM_TRGO_UPDATE
TIM3.Channel-PWM\ Generation4\ CH4=TIM_CHANNEL_4
TIM7.Period=124
TIM7.Prescaler=274
TIM7.TIM_MasterOutputTrigger=TIM_TRGO_UPDATE
UART5.BaudRate=100000
UART5.FIFOMode=FIFOMODE_DISABLE
UART5.Mode=MODE_RX
UART5.Parity=PARITY_EVEN
UART5.StopBits=UART_STOPBITS_1
UART5.WordLength=WORDLENGTH_9B
USART1.VirtualMode-Asynchronous=VM_ASYNC
USART10.VirtualMode=VM_ASYNC
USART2.BaudRate=1919810
USART2.OverSampling=UART_OVERSAMPLING_8
USART2.UART_DEAssertionTime=2
USART2.UART_DEDeassertionTime=2
USART2.VirtualMode-Asynchronous=VM_ASYNC
USART2.VirtualMode-Hardware\ Flow\ Control\ (RS485)=VM_ASYNC
USART3.BaudRate=1919810
USART3.OverSampling=UART_OVERSAMPLING_8
USART3.UART_DEAssertionTime=2
USART3.UART_DEDeassertionTime=2
USART3.VirtualMode-Asynchronous=VM_ASYNC
USART3.VirtualMode-Hardware\ Flow\ Control\ (RS485)=VM_ASYNC
USB_DEVICE.CLASS_NAME_HS=CDC
USB_DEVICE.VirtualMode=Cdc
USB_DEVICE.VirtualModeHS=Cdc_HS
USB_OTG_HS.VirtualMode-Device_Only_FS=Device_Only_FS
VP_ADC3_TempSens_Input.Mode=IN-TempSens
VP_CRC_VS_CRC.Mode=CRC_Activate
VP_FREERTOS_VS_CMSIS_V2.Mode=CMSIS_V2
VP_IWDG1_VS_IWDG.Mode=IWDG_Activate
VP_MEMORYMAP_VS_MEMORYMAP.Mode=CurAppReg
VP_SYS_VS_tim6.Mode=TIM6
VP_TIM12_VS_ClockSourceINT.Mode=Internal
VP_TIM23_VS_ClockSourceINT.Mode=Internal
VP_TIM3_VS_ClockSourceINT.Mode=Internal
VP_TIM7_VS_ClockSourceINT.Mode=Enable_Timer
VP_USB_DEVICE_VS_USB_DEVICE_CDC_HS.Mode=CDC_HS
board=custom

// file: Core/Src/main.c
/* USER CODE BEGIN Header */
/**
  ******************************************************************************
  * @file           : main.c
  * @brief          : Main program body
  ******************************************************************************
  * @attention
  *
  * Copyright (c) 2026 STMicroelectronics.
  * All rights reserved.
  *
  * This software is licensed under terms that can be found in the LICENSE file
  * in the root directory of this software component.
  * If no LICENSE file comes with this software, it is provided AS-IS.
  *
  ******************************************************************************
  */
/* USER CODE END Header */
#include "main.h"
#include "FreeRTOS.h"
#include "cmsis_os2.h"
#include "adc.h"
#include "bdma.h"
#include "crc.h"
#include "dma.h"
#include "fdcan.h"
#include "iwdg.h"
#include "spi.h"
#include "tim.h"
#include "usart.h"
#include "usb_device.h"
#include "gpio.h"

void SystemClock_Config(void);
void PeriphCommonClock_Config(void);
static void MPU_Config(void);
void MX_FREERTOS_Init(void);

int main(void)
{

  /* MPU Configuration--------------------------------------------------------*/
  MPU_Config();

  /* Enable the CPU Cache */

  /* Enable I-Cache---------------------------------------------------------*/
  SCB_EnableICache();

  /* Enable D-Cache---------------------------------------------------------*/
  SCB_EnableDCache();

  /* MCU Configuration--------------------------------------------------------*/

  /* Reset of all peripherals, Initializes the Flash interface and the Systick. */
  HAL_Init();

  /* USER CODE BEGIN Init */

  __HAL_DBGMCU_FREEZE_IWDG1();

  /* USER CODE END Init */

  /* Configure the system clock */
  SystemClock_Config();

  /* Configure the peripherals common clocks */
  PeriphCommonClock_Config();

  /* Initialize all configured peripherals */
  MX_GPIO_Init();
  MX_DMA_Init();
  MX_BDMA_Init();
  MX_ADC3_Init();
  MX_FDCAN1_Init();
  MX_FDCAN2_Init();
  MX_FDCAN3_Init();
  MX_SPI2_Init();
  MX_SPI6_Init();
  MX_TIM3_Init();
  MX_TIM12_Init();
  MX_UART5_Init();
  MX_UART7_Init();
  MX_USART1_UART_Init();
  MX_USART3_UART_Init();
  MX_CRC_Init();
  MX_USART10_UART_Init();
  MX_USART2_UART_Init();
  MX_TIM7_Init();
  MX_TIM23_Init();
  MX_IWDG1_Init();
  MX_ADC1_Init();

  /* Init scheduler */
  osKernelInitialize();  /* Call init function for freertos objects (in cmsis_os2.c) */
  MX_FREERTOS_Init();

  /* Start scheduler */
  osKernelStart();

  /* We should never get here as control is now taken by the scheduler */

  /* Infinite loop */
  while (1)
  {

  }
}

void SystemClock_Config(void)
{
  RCC_OscInitTypeDef RCC_OscInitStruct = {0};
  RCC_ClkInitTypeDef RCC_ClkInitStruct = {0};

  /** Supply configuration update enable
  */
  HAL_PWREx_ConfigSupply(PWR_LDO_SUPPLY);

  /** Configure the main internal regulator output voltage
  */
  __HAL_PWR_VOLTAGESCALING_CONFIG(PWR_REGULATOR_VOLTAGE_SCALE0);

  while(!__HAL_PWR_GET_FLAG(PWR_FLAG_VOSRDY)) {}

  /** Initializes the RCC Oscillators according to the specified parameters
  * in the RCC_OscInitTypeDef structure.
  */
  RCC_OscInitStruct.OscillatorType = RCC_OSCILLATORTYPE_LSI|RCC_OSCILLATORTYPE_HSE;
  RCC_OscInitStruct.HSEState = RCC_HSE_ON;
  RCC_OscInitStruct.LSIState = RCC_LSI_ON;
  RCC_OscInitStruct.PLL.PLLState = RCC_PLL_ON;
  RCC_OscInitStruct.PLL.PLLSource = RCC_PLLSOURCE_HSE;
  RCC_OscInitStruct.PLL.PLLM = 3;
  RCC_OscInitStruct.PLL.PLLN = 68;
  RCC_OscInitStruct.PLL.PLLP = 1;
  RCC_OscInitStruct.PLL.PLLQ = 5;
  RCC_OscInitStruct.PLL.PLLR = 2;
  RCC_OscInitStruct.PLL.PLLRGE = RCC_PLL1VCIRANGE_3;
  RCC_OscInitStruct.PLL.PLLVCOSEL = RCC_PLL1VCOWIDE;
  RCC_OscInitStruct.PLL.PLLFRACN = 6144;
  if (HAL_RCC_OscConfig(&RCC_OscInitStruct) != HAL_OK)
  {
    Error_Handler();
  }

  /** Initializes the CPU, AHB and APB buses clocks
  */
  RCC_ClkInitStruct.ClockType = RCC_CLOCKTYPE_HCLK|RCC_CLOCKTYPE_SYSCLK
                              |RCC_CLOCKTYPE_PCLK1|RCC_CLOCKTYPE_PCLK2
                              |RCC_CLOCKTYPE_D3PCLK1|RCC_CLOCKTYPE_D1PCLK1;
  RCC_ClkInitStruct.SYSCLKSource = RCC_SYSCLKSOURCE_PLLCLK;
  RCC_ClkInitStruct.SYSCLKDivider = RCC_SYSCLK_DIV1;
  RCC_ClkInitStruct.AHBCLKDivider = RCC_HCLK_DIV2;
  RCC_ClkInitStruct.APB3CLKDivider = RCC_APB3_DIV2;
  RCC_ClkInitStruct.APB1CLKDivider = RCC_APB1_DIV2;
  RCC_ClkInitStruct.APB2CLKDivider = RCC_APB2_DIV2;
  RCC_ClkInitStruct.APB4CLKDivider = RCC_APB4_DIV2;

  if (HAL_RCC_ClockConfig(&RCC_ClkInitStruct, FLASH_LATENCY_3) != HAL_OK)
  {
    Error_Handler();
  }
}

void PeriphCommonClock_Config(void)
{
  RCC_PeriphCLKInitTypeDef PeriphClkInitStruct = {0};

  /** Initializes the peripherals clock
  */
  PeriphClkInitStruct.PeriphClockSelection = RCC_PERIPHCLK_USB|RCC_PERIPHCLK_SPI6
                              |RCC_PERIPHCLK_ADC|RCC_PERIPHCLK_SPI2
                              |RCC_PERIPHCLK_FDCAN;
  PeriphClkInitStruct.PLL2.PLL2M = 8;
  PeriphClkInitStruct.PLL2.PLL2N = 80;
  PeriphClkInitStruct.PLL2.PLL2P = 3;
  PeriphClkInitStruct.PLL2.PLL2Q = 3;
  PeriphClkInitStruct.PLL2.PLL2R = 2;
  PeriphClkInitStruct.PLL2.PLL2RGE = RCC_PLL2VCIRANGE_1;
  PeriphClkInitStruct.PLL2.PLL2VCOSEL = RCC_PLL2VCOWIDE;
  PeriphClkInitStruct.PLL2.PLL2FRACN = 0;
  PeriphClkInitStruct.PLL3.PLL3M = 16;
  PeriphClkInitStruct.PLL3.PLL3N = 160;
  PeriphClkInitStruct.PLL3.PLL3P = 1;
  PeriphClkInitStruct.PLL3.PLL3Q = 5;
  PeriphClkInitStruct.PLL3.PLL3R = 2;
  PeriphClkInitStruct.PLL3.PLL3RGE = RCC_PLL3VCIRANGE_0;
  PeriphClkInitStruct.PLL3.PLL3VCOSEL = RCC_PLL3VCOMEDIUM;
  PeriphClkInitStruct.PLL3.PLL3FRACN = 0;
  PeriphClkInitStruct.Spi123ClockSelection = RCC_SPI123CLKSOURCE_PLL2;
  PeriphClkInitStruct.FdcanClockSelection = RCC_FDCANCLKSOURCE_PLL2;
  PeriphClkInitStruct.UsbClockSelection = RCC_USBCLKSOURCE_PLL3;
  PeriphClkInitStruct.AdcClockSelection = RCC_ADCCLKSOURCE_PLL2;
  PeriphClkInitStruct.Spi6ClockSelection = RCC_SPI6CLKSOURCE_PLL3;
  if (HAL_RCCEx_PeriphCLKConfig(&PeriphClkInitStruct) != HAL_OK)
  {
    Error_Handler();
  }
}

 /* MPU Configuration */

void MPU_Config(void)
{
  MPU_Region_InitTypeDef MPU_InitStruct = {0};

  /* Disables the MPU */
  HAL_MPU_Disable();

  /** Initializes and configures the Region and the memory to be protected
  */
  MPU_InitStruct.Enable = MPU_REGION_ENABLE;
  MPU_InitStruct.Number = MPU_REGION_NUMBER0;
  MPU_InitStruct.BaseAddress = 0x0;
  MPU_InitStruct.Size = MPU_REGION_SIZE_4GB;
  MPU_InitStruct.SubRegionDisable = 0x87;
  MPU_InitStruct.TypeExtField = MPU_TEX_LEVEL0;
  MPU_InitStruct.AccessPermission = MPU_REGION_NO_ACCESS;
  MPU_InitStruct.DisableExec = MPU_INSTRUCTION_ACCESS_DISABLE;
  MPU_InitStruct.IsShareable = MPU_ACCESS_NOT_SHAREABLE;
  MPU_InitStruct.IsCacheable = MPU_ACCESS_NOT_CACHEABLE;
  MPU_InitStruct.IsBufferable = MPU_ACCESS_NOT_BUFFERABLE;

  HAL_MPU_ConfigRegion(&MPU_InitStruct);

  /** Initializes and configures the Region and the memory to be protected
  */
  MPU_InitStruct.Number = MPU_REGION_NUMBER1;
  MPU_InitStruct.BaseAddress = 0x00000000;
  MPU_InitStruct.Size = MPU_REGION_SIZE_64KB;
  MPU_InitStruct.SubRegionDisable = 0x0;
  MPU_InitStruct.TypeExtField = MPU_TEX_LEVEL1;
  MPU_InitStruct.AccessPermission = MPU_REGION_FULL_ACCESS;
  MPU_InitStruct.DisableExec = MPU_INSTRUCTION_ACCESS_ENABLE;

  HAL_MPU_ConfigRegion(&MPU_InitStruct);

  /** Initializes and configures the Region and the memory to be protected
  */
  MPU_InitStruct.Number = MPU_REGION_NUMBER2;
  MPU_InitStruct.BaseAddress = 0x20000000;
  MPU_InitStruct.Size = MPU_REGION_SIZE_128KB;
  MPU_InitStruct.DisableExec = MPU_INSTRUCTION_ACCESS_DISABLE;

  HAL_MPU_ConfigRegion(&MPU_InitStruct);

  /** Initializes and configures the Region and the memory to be protected
  */
  MPU_InitStruct.Number = MPU_REGION_NUMBER3;
  MPU_InitStruct.BaseAddress = 0x24000000;
  MPU_InitStruct.Size = MPU_REGION_SIZE_512KB;
  MPU_InitStruct.SubRegionDisable = 0xE0;
  MPU_InitStruct.IsCacheable = MPU_ACCESS_CACHEABLE;
  MPU_InitStruct.IsBufferable = MPU_ACCESS_BUFFERABLE;

  HAL_MPU_ConfigRegion(&MPU_InitStruct);

  /** Initializes and configures the Region and the memory to be protected
  */
  MPU_InitStruct.Number = MPU_REGION_NUMBER4;
  MPU_InitStruct.BaseAddress = 0x30000000;
  MPU_InitStruct.Size = MPU_REGION_SIZE_32KB;
  MPU_InitStruct.SubRegionDisable = 0x0;
  MPU_InitStruct.IsShareable = MPU_ACCESS_SHAREABLE;
  MPU_InitStruct.IsCacheable = MPU_ACCESS_NOT_CACHEABLE;
  MPU_InitStruct.IsBufferable = MPU_ACCESS_NOT_BUFFERABLE;

  HAL_MPU_ConfigRegion(&MPU_InitStruct);

  /** Initializes and configures the Region and the memory to be protected
  */
  MPU_InitStruct.Number = MPU_REGION_NUMBER5;
  MPU_InitStruct.BaseAddress = 0x38000000;
  MPU_InitStruct.Size = MPU_REGION_SIZE_16KB;

  HAL_MPU_ConfigRegion(&MPU_InitStruct);

  /** Initializes and configures the Region and the memory to be protected
  */
  MPU_InitStruct.Number = MPU_REGION_NUMBER6;
  MPU_InitStruct.BaseAddress = 0x40000000;
  MPU_InitStruct.Size = MPU_REGION_SIZE_512MB;
  MPU_InitStruct.TypeExtField = MPU_TEX_LEVEL0;
  MPU_InitStruct.IsBufferable = MPU_ACCESS_BUFFERABLE;

  HAL_MPU_ConfigRegion(&MPU_InitStruct);

  /** Initializes and configures the Region and the memory to be protected
  */
  MPU_InitStruct.Number = MPU_REGION_NUMBER7;
  MPU_InitStruct.BaseAddress = 0x8000000;
  MPU_InitStruct.Size = MPU_REGION_SIZE_1MB;
  MPU_InitStruct.DisableExec = MPU_INSTRUCTION_ACCESS_ENABLE;
  MPU_InitStruct.IsShareable = MPU_ACCESS_NOT_SHAREABLE;
  MPU_InitStruct.IsCacheable = MPU_ACCESS_CACHEABLE;

  HAL_MPU_ConfigRegion(&MPU_InitStruct);
  /* Enables the MPU */
  HAL_MPU_Enable(MPU_PRIVILEGED_DEFAULT);

}

void HAL_TIM_PeriodElapsedCallback(TIM_HandleTypeDef *htim)
{
  if (htim->Instance == TIM6)
  {
    HAL_IncTick();
  }
}

void Error_Handler(void)
{
  __disable_irq();
  while (1)
  {
  }
}

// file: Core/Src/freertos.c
/* USER CODE BEGIN Header */
/**
  ******************************************************************************
  * File Name          : freertos.c
  * Description        : Code for freertos applications
  ******************************************************************************
  * @attention
  *
  * Copyright (c) 2026 STMicroelectronics.
  * All rights reserved.
  *
  * This software is licensed under terms that can be found in the LICENSE file
  * in the root directory of this software component.
  * If no LICENSE file comes with this software, it is provided AS-IS.
  *
  ******************************************************************************
  */
/* USER CODE END Header */

#include "FreeRTOS.h"
#include "task.h"
#include "main.h"
#include "FreeRTOS.h"
#include "cmsis_os2.h"

/* Definitions for defaultTask */
osThreadId_t defaultTaskHandle;
const osThreadAttr_t defaultTask_attributes = {
  .name = "defaultTask",
  .stack_size = 256 * 4,
  .priority = (osPriority_t) osPriorityRealtime,
};
/* Definitions for errorTask */
osThreadId_t errorTaskHandle;
const osThreadAttr_t errorTask_attributes = {
  .name = "errorTask",
  .stack_size = 256 * 4,
  .priority = (osPriority_t) osPriorityHigh,
};
/* Definitions for remoteCtrlTask */
osThreadId_t remoteCtrlTaskHandle;
const osThreadAttr_t remoteCtrlTask_attributes = {
  .name = "remoteCtrlTask",
  .stack_size = 256 * 4,
  .priority = (osPriority_t) osPriorityHigh,
};
/* Definitions for daemonTask */
osThreadId_t daemonTaskHandle;
const osThreadAttr_t daemonTask_attributes = {
  .name = "daemonTask",
  .stack_size = 256 * 4,
  .priority = (osPriority_t) osPriorityNormal,
};
/* Definitions for hostTask */
osThreadId_t hostTaskHandle;
const osThreadAttr_t hostTask_attributes = {
  .name = "hostTask",
  .stack_size = 256 * 4,
  .priority = (osPriority_t) osPriorityHigh,
};
/* Definitions for wdgTask */
osThreadId_t wdgTaskHandle;
const osThreadAttr_t wdgTask_attributes = {
  .name = "wdgTask",
  .stack_size = 128 * 4,
  .priority = (osPriority_t) osPriorityBelowNormal,
};
/* Definitions for chassisTask */
osThreadId_t chassisTaskHandle;
const osThreadAttr_t chassisTask_attributes = {
  .name = "chassisTask",
  .stack_size = 256 * 4,
  .priority = (osPriority_t) osPriorityNormal,
};
/* Definitions for roboarmTask */
osThreadId_t roboarmTaskHandle;
const osThreadAttr_t roboarmTask_attributes = {
  .name = "roboarmTask",
  .stack_size = 512 * 4,
  .priority = (osPriority_t) osPriorityNormal,
};
/* Definitions for imuTask */
osThreadId_t imuTaskHandle;
const osThreadAttr_t imuTask_attributes = {
  .name = "imuTask",
  .stack_size = 256 * 4,
  .priority = (osPriority_t) osPriorityHigh,
};
/* Definitions for refereeTask */
osThreadId_t refereeTaskHandle;
const osThreadAttr_t refereeTask_attributes = {
  .name = "refereeTask",
  .stack_size = 256 * 4,
  .priority = (osPriority_t) osPriorityHigh,
};

void TaskStart(void *argument);
extern void TaskError(void *argument);
extern void TaskRemoteCtrl(void *argument);
extern void TaskDaemon(void *argument);
extern void TaskHost(void *argument);
extern void Taskwdg(void *argument);
extern void TaskChassis(void *argument);
extern void TaskRoboarm(void *argument);
extern void TaskImu(void *argument);
extern void TaskReferee(void *argument);

extern void MX_USB_DEVICE_Init(void);
void MX_FREERTOS_Init(void); /* (MISRA C 2004 rule 8.1) */

void MX_FREERTOS_Init(void) {

  /* Create the thread(s) */
  /* creation of defaultTask */
  defaultTaskHandle = osThreadNew(TaskStart, NULL, &defaultTask_attributes);

  /* creation of errorTask */
  errorTaskHandle = osThreadNew(TaskError, NULL, &errorTask_attributes);

  /* creation of remoteCtrlTask */
  remoteCtrlTaskHandle = osThreadNew(TaskRemoteCtrl, NULL, &remoteCtrlTask_attributes);

  /* creation of daemonTask */
  daemonTaskHandle = osThreadNew(TaskDaemon, NULL, &daemonTask_attributes);

  /* creation of hostTask */
  hostTaskHandle = osThreadNew(TaskHost, NULL, &hostTask_attributes);

  /* creation of wdgTask */
  wdgTaskHandle = osThreadNew(Taskwdg, NULL, &wdgTask_attributes);

  /* creation of chassisTask */
  chassisTaskHandle = osThreadNew(TaskChassis, NULL, &chassisTask_attributes);

  /* creation of roboarmTask */
  roboarmTaskHandle = osThreadNew(TaskRoboarm, NULL, &roboarmTask_attributes);

  /* creation of imuTask */
  imuTaskHandle = osThreadNew(TaskImu, NULL, &imuTask_attributes);

  /* creation of refereeTask */
  refereeTaskHandle = osThreadNew(TaskReferee, NULL, &refereeTask_attributes);

}

__weak void TaskStart(void *argument)
{
  /* init code for USB_DEVICE */
  MX_USB_DEVICE_Init();
  for(;;)
  {
    osDelay(1);
  }
}
